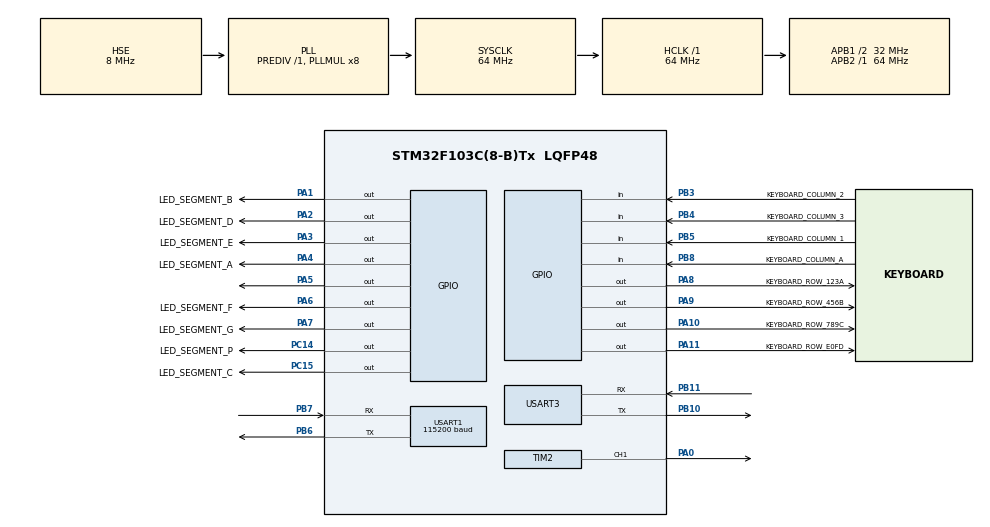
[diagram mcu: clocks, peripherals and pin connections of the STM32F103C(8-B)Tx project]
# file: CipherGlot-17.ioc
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Dma.Request0=USART3_RX
Dma.USART3_RX.0.Direction=DMA_PERIPH_TO_MEMORY
Dma.USART3_RX.0.Instance=DMA1_Channel3
Dma.USART3_RX.0.MemDataAlignment=DMA_MDATAALIGN_BYTE
Dma.USART3_RX.0.MemInc=DMA_MINC_ENABLE
Dma.USART3_RX.0.Mode=DMA_CIRCULAR
Dma.USART3_RX.0.PeriphDataAlignment=DMA_PDATAALIGN_BYTE
Dma.USART3_RX.0.PeriphInc=DMA_PINC_DISABLE
Dma.USART3_RX.0.Priority=DMA_PRIORITY_LOW
Mcu.Family=STM32F1
Mcu.Name=STM32F103C(8-B)Tx
Mcu.Package=LQFP48
NVIC.DMA1_Channel3_IRQn=true\:0\:0\:false\:false\:true\:false\:true
NVIC.PriorityGroup=NVIC_PRIORITYGROUP_4
NVIC.TIM1_UP_IRQn=true\:0\:0\:false\:false\:true\:true\:true
NVIC.TIM3_IRQn=true\:0\:0\:false\:false\:true\:true\:true
NVIC.TIM4_IRQn=true\:0\:0\:false\:false\:true\:true\:true
PA0-WKUP.Signal=S_TIM2_CH1_ETR
PA1.GPIO_Label=LED_SEGMENT_B
PA1.Signal=GPIO_Output
PA10.GPIO_Label=KEYBOARD_ROW_789C
PA10.Signal=GPIO_Output
PA11.GPIO_Label=KEYBOARD_ROW_E0FD
PA11.Signal=GPIO_Output
PA13.Mode=Serial_Wire
PA13.Signal=SYS_JTMS-SWDIO
PA14.Mode=Serial_Wire
PA14.Signal=SYS_JTCK-SWCLK
PA2.GPIO_Label=LED_SEGMENT_D
PA2.Signal=GPIO_Output
PA3.GPIO_Label=LED_SEGMENT_E
PA3.Signal=GPIO_Output
PA4.GPIO_Label=LED_SEGMENT_A
PA4.Signal=GPIO_Output
PA5.Signal=GPIO_Output
PA6.GPIO_Label=LED_SEGMENT_F
PA6.Signal=GPIO_Output
PA7.GPIO_Label=LED_SEGMENT_G
PA7.Signal=GPIO_Output
PA8.GPIO_Label=KEYBOARD_ROW_123A
PA8.Signal=GPIO_Output
PA9.GPIO_Label=KEYBOARD_ROW_456B
PA9.Signal=GPIO_Output
PB10.Mode=Asynchronous
PB10.Signal=USART3_TX
PB11.Mode=Asynchronous
PB11.Signal=USART3_RX
PB3.GPIO_Label=KEYBOARD_COLUMN_2
PB3.GPIO_PuPd=GPIO_PULLDOWN
PB3.Signal=GPIO_Input
PB4.GPIO_Label=KEYBOARD_COLUMN_3
PB4.GPIO_PuPd=GPIO_PULLDOWN
PB4.Signal=GPIO_Input
PB5.GPIO_Label=KEYBOARD_COLUMN_1
PB5.GPIO_PuPd=GPIO_PULLDOWN
PB5.Signal=GPIO_Input
PB6.Mode=Asynchronous
PB6.Signal=USART1_TX
PB7.Mode=Asynchronous
PB7.Signal=USART1_RX
PB8.GPIO_Label=KEYBOARD_COLUMN_A
PB8.GPIO_PuPd=GPIO_PULLDOWN
PB8.Signal=GPIO_Input
PC14-OSC32_IN.GPIO_Label=LED_SEGMENT_P
PC14-OSC32_IN.Signal=GPIO_Output
PC15-OSC32_OUT.GPIO_Label=LED_SEGMENT_C
PC15-OSC32_OUT.Signal=GPIO_Output
PD0-OSC_IN.Mode=HSE-External-Oscillator
PD0-OSC_IN.Signal=RCC_OSC_IN
PD1-OSC_OUT.Mode=HSE-External-Oscillator
PD1-OSC_OUT.Signal=RCC_OSC_OUT
ProjectManager.HeapSize=0x200
ProjectManager.StackSize=0x400
ProjectManager.TargetToolchain=STM32CubeIDE
RCC.AHBFreq_Value=64000000
RCC.APB1CLKDivider=RCC_HCLK_DIV2
RCC.APB1Freq_Value=32000000
RCC.APB1TimFreq_Value=64000000
RCC.APB2Freq_Value=64000000
RCC.APB2TimFreq_Value=64000000
RCC.HCLKFreq_Value=64000000
RCC.PLLMUL=RCC_PLL_MUL8
RCC.PLLSourceVirtual=RCC_PLLSOURCE_HSE
RCC.SYSCLKFreq_VALUE=64000000
RCC.SYSCLKSource=RCC_SYSCLKSOURCE_PLLCLK
RCC.USBFreq_Value=64000000
RTC.Format=RTC_FORMAT_BIN
RTC.Hours=0
SH.S_TIM2_CH1_ETR.0=TIM2_CH1,PWM Generation1 CH1
TIM1.Period=300-1
TIM1.Prescaler=64000-1
TIM2.Channel-PWM\ Generation1\ CH1=TIM_CHANNEL_1
TIM2.Period=1000-1
TIM2.Prescaler=32-1
TIM2.Pulse-PWM\ Generation1\ CH1=500-1
TIM3.Period=1500-1
TIM3.Prescaler=64000-1
TIM4.Period=1000-1
TIM4.Prescaler=64000-1
USART1.BaudRate=115200
USART1.VirtualMode=VM_ASYNC
USART3.VirtualMode=VM_ASYNC
VP_RTC_VS_RTC_Activate.Mode=RTC_Enabled
VP_RTC_VS_RTC_Calendar.Mode=RTC_Calendar
VP_TIM1_VS_ClockSourceINT.Mode=Internal
VP_TIM3_VS_ClockSourceINT.Mode=Internal
VP_TIM4_VS_ClockSourceINT.Mode=Internal
board=custom

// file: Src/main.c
/* USER CODE BEGIN Header */
/**
  ******************************************************************************
  * @file           : main.c
  * @brief          : Main program body
  ******************************************************************************
  * @attention
  *
  * <h2><center>&copy; Copyright (c) 2020 STMicroelectronics.
  * All rights reserved.</center></h2>
  *
  * This software component is licensed by ST under BSD 3-Clause license,
  * the "License"; You may not use this file except in compliance with the
  * License. You may obtain a copy of the License at:
  *                        opensource.org/licenses/BSD-3-Clause
  *
  ******************************************************************************
  */
/* USER CODE END Header */
#include "main.h"
#include "dma.h"
#include "rtc.h"
#include "tim.h"
#include "usart.h"
#include "gpio.h"

/* USER CODE BEGIN Includes */

	#include "cipherglot17_sm.h"
	#include "ringbuffer_dma_sm.h"

/* USER CODE END Includes */

/* USER CODE BEGIN PV */
/* Private variables ---------------------------------------------------------*/

/* USER CODE END PV */

void SystemClock_Config(void);
/* USER CODE BEGIN PFP */
/* Private function prototypes -----------------------------------------------*/

/* USER CODE END PFP */

int main(void)
{

  /* MCU Configuration--------------------------------------------------------*/

  /* Reset of all peripherals, Initializes the Flash interface and the Systick. */
  HAL_Init();

  /* Configure the system clock */
  SystemClock_Config();

  /* Initialize all configured peripherals */
  MX_GPIO_Init();
  MX_DMA_Init();
  MX_RTC_Init();
  MX_TIM2_Init();
  MX_TIM3_Init();
  MX_TIM4_Init();
  MX_USART1_UART_Init();
  MX_USART3_UART_Init();
  MX_TIM1_Init();
  /* USER CODE BEGIN 2 */

  	  CipherGlot_init();

  /* USER CODE END 2 */

  /* Infinite loop */
  /* USER CODE BEGIN WHILE */
  while (1)
  {
	  CipherGlot_main();

    /* USER CODE END WHILE */

  }
}

void SystemClock_Config(void)
{
  RCC_OscInitTypeDef RCC_OscInitStruct = {0};
  RCC_ClkInitTypeDef RCC_ClkInitStruct = {0};
  RCC_PeriphCLKInitTypeDef PeriphClkInit = {0};

  /** Initializes the RCC Oscillators according to the specified parameters
  * in the RCC_OscInitTypeDef structure.
  */
  RCC_OscInitStruct.OscillatorType = RCC_OSCILLATORTYPE_LSI|RCC_OSCILLATORTYPE_HSE;
  RCC_OscInitStruct.HSEState = RCC_HSE_ON;
  RCC_OscInitStruct.HSEPredivValue = RCC_HSE_PREDIV_DIV1;
  RCC_OscInitStruct.HSIState = RCC_HSI_ON;
  RCC_OscInitStruct.LSIState = RCC_LSI_ON;
  RCC_OscInitStruct.PLL.PLLState = RCC_PLL_ON;
  RCC_OscInitStruct.PLL.PLLSource = RCC_PLLSOURCE_HSE;
  RCC_OscInitStruct.PLL.PLLMUL = RCC_PLL_MUL8;
  if (HAL_RCC_OscConfig(&RCC_OscInitStruct) != HAL_OK)
  {
    Error_Handler();
  }
  /** Initializes the CPU, AHB and APB buses clocks
  */
  RCC_ClkInitStruct.ClockType = RCC_CLOCKTYPE_HCLK|RCC_CLOCKTYPE_SYSCLK
                              |RCC_CLOCKTYPE_PCLK1|RCC_CLOCKTYPE_PCLK2;
  RCC_ClkInitStruct.SYSCLKSource = RCC_SYSCLKSOURCE_PLLCLK;
  RCC_ClkInitStruct.AHBCLKDivider = RCC_SYSCLK_DIV1;
  RCC_ClkInitStruct.APB1CLKDivider = RCC_HCLK_DIV2;
  RCC_ClkInitStruct.APB2CLKDivider = RCC_HCLK_DIV1;

  if (HAL_RCC_ClockConfig(&RCC_ClkInitStruct, FLASH_LATENCY_2) != HAL_OK)
  {
    Error_Handler();
  }
  PeriphClkInit.PeriphClockSelection = RCC_PERIPHCLK_RTC;
  PeriphClkInit.RTCClockSelection = RCC_RTCCLKSOURCE_LSI;
  if (HAL_RCCEx_PeriphCLKConfig(&PeriphClkInit) != HAL_OK)
  {
    Error_Handler();
  }
}

void Error_Handler(void)
{
  while(1)
  {
  }
}
